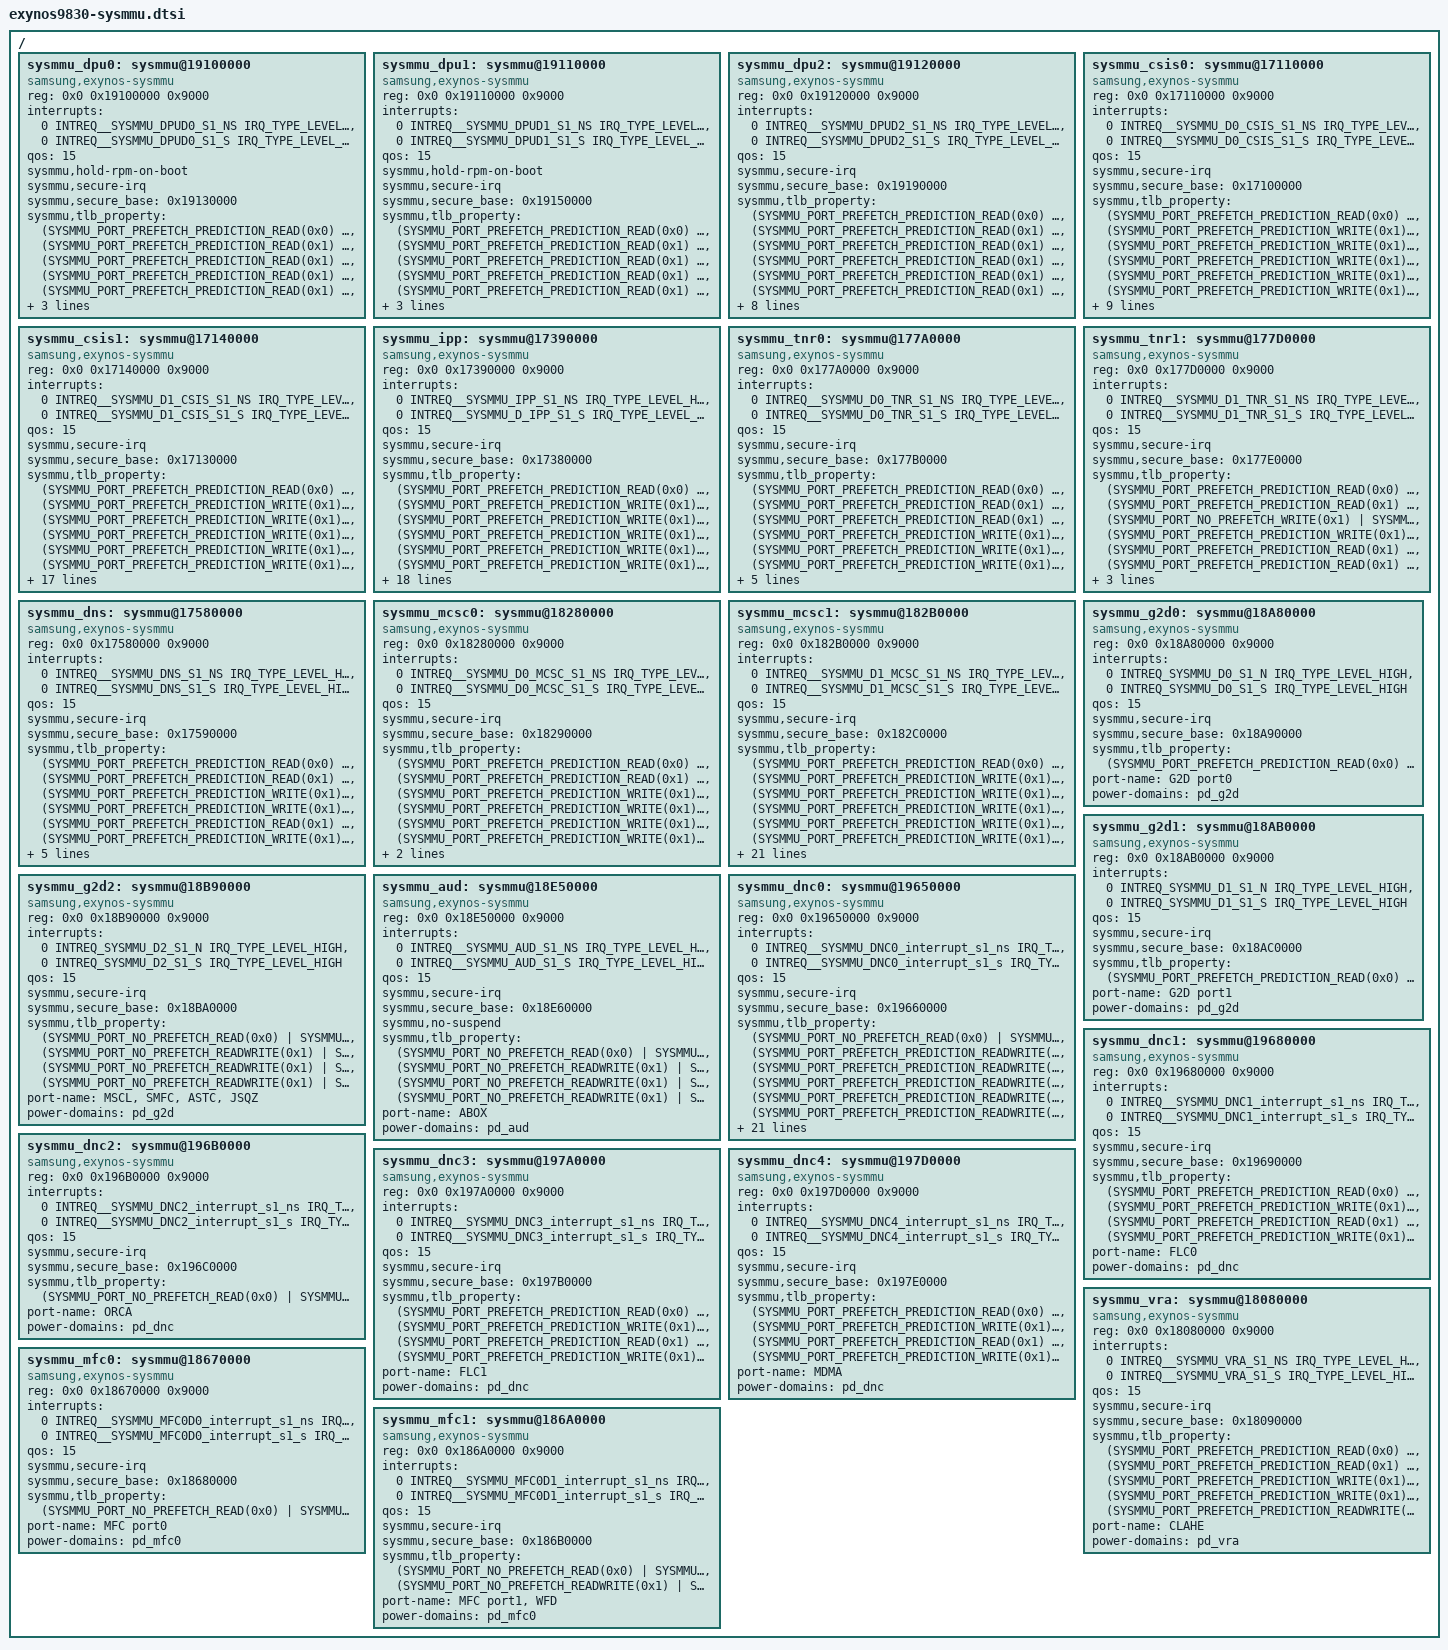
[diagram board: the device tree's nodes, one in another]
/*
 * SAMSUNG EXYNOS9830 SoC device tree source
 *
 * Copyright (c) 2018 Samsung Electronics Co., Ltd.
 *		http://www.samsung.com
 *
 * SAMSUNG EXYNOS9830 SoC device nodes are listed in this file.
 * EXYNOS9830 based board files can include this file and provide
 * values for board specfic bindings.
 *
 * This program is free software; you can redistribute it and/or modify
 * it under the terms of the GNU General Public License version 2 as
 * published by the Free Software Foundation.
 */

#include <dt-bindings/interrupt-controller/arm-gic.h>
#include <dt-bindings/sysmmu/sysmmu.h>

/ {
	sysmmu_dpu0: sysmmu@19100000 {
		compatible = "samsung,exynos-sysmmu";
		reg = <0x0 0x19100000 0x9000>;
		interrupts = <0 INTREQ__SYSMMU_DPUD0_S1_NS IRQ_TYPE_LEVEL_HIGH>,
			     <0 INTREQ__SYSMMU_DPUD0_S1_S IRQ_TYPE_LEVEL_HIGH>;
		qos = <15>;

		sysmmu,hold-rpm-on-boot;
		sysmmu,secure-irq;
		sysmmu,secure_base = <0x19130000>;
		sysmmu,tlb_property =
			<(SYSMMU_PORT_PREFETCH_PREDICTION_READ(0x0) | SYSMMU_BL1)  SYSMMU_NOID>,
			<(SYSMMU_PORT_PREFETCH_PREDICTION_READ(0x1) | SYSMMU_BL1)  SYSMMU_ID_MASK(0x4,  0x1C)>,
			<(SYSMMU_PORT_PREFETCH_PREDICTION_READ(0x1) | SYSMMU_BL32) SYSMMU_ID_MASK(0x10, 0x1C)>,
			<(SYSMMU_PORT_PREFETCH_PREDICTION_READ(0x1) | SYSMMU_BL32) SYSMMU_ID_MASK(0x14, 0x1C)>,
			<(SYSMMU_PORT_PREFETCH_PREDICTION_READ(0x1) | SYSMMU_BL8)  SYSMMU_ID_MASK(0x18, 0x1C)>,
			<(SYSMMU_PORT_PREFETCH_PREDICTION_READ(0x1) | SYSMMU_BL8)  SYSMMU_ID_MASK(0x1C, 0x1C)>;
		port-name = "L0, L5";
		#iommu-cells = <0>;
		power-domains = <&pd_dpu>;
	};

	sysmmu_dpu1: sysmmu@19110000 {
		compatible = "samsung,exynos-sysmmu";
		reg = <0x0 0x19110000 0x9000>;
		interrupts = <0 INTREQ__SYSMMU_DPUD1_S1_NS IRQ_TYPE_LEVEL_HIGH>,
			     <0 INTREQ__SYSMMU_DPUD1_S1_S IRQ_TYPE_LEVEL_HIGH>;
		qos = <15>;

		sysmmu,hold-rpm-on-boot;
		sysmmu,secure-irq;
		sysmmu,secure_base = <0x19150000>;
		sysmmu,tlb_property =
			<(SYSMMU_PORT_PREFETCH_PREDICTION_READ(0x0) | SYSMMU_BL1) SYSMMU_NOID>,
			<(SYSMMU_PORT_PREFETCH_PREDICTION_READ(0x1) | SYSMMU_BL1) SYSMMU_ID_MASK(0x4,  0x1C)>,
			<(SYSMMU_PORT_PREFETCH_PREDICTION_READ(0x1) | SYSMMU_BL1) SYSMMU_ID_MASK(0x10, 0x1C)>,
			<(SYSMMU_PORT_PREFETCH_PREDICTION_READ(0x1) | SYSMMU_BL1) SYSMMU_ID_MASK(0x14, 0x1C)>,
			<(SYSMMU_PORT_PREFETCH_PREDICTION_READ(0x1) | SYSMMU_BL1) SYSMMU_ID_MASK(0x18, 0x1C)>,
			<(SYSMMU_PORT_PREFETCH_PREDICTION_READ(0x1) | SYSMMU_BL1) SYSMMU_ID_MASK(0x1C, 0x1C)>;
		port-name = "L1, L4";
		#iommu-cells = <0>;
		power-domains = <&pd_dpu>;
	};

	sysmmu_dpu2: sysmmu@19120000 {
		compatible = "samsung,exynos-sysmmu";
		reg = <0x0 0x19120000 0x9000>;
		interrupts = <0 INTREQ__SYSMMU_DPUD2_S1_NS IRQ_TYPE_LEVEL_HIGH>,
			     <0 INTREQ__SYSMMU_DPUD2_S1_S IRQ_TYPE_LEVEL_HIGH>;
		qos = <15>;

		sysmmu,secure-irq;
		sysmmu,secure_base = <0x19190000>;
		sysmmu,tlb_property =
			<(SYSMMU_PORT_PREFETCH_PREDICTION_READ(0x0)  | SYSMMU_BL1) SYSMMU_NOID>,
			<(SYSMMU_PORT_PREFETCH_PREDICTION_READ(0x1)  | SYSMMU_BL1) SYSMMU_ID_MASK(0x4,  0x1C)>,
			<(SYSMMU_PORT_PREFETCH_PREDICTION_READ(0x1)  | SYSMMU_BL1) SYSMMU_ID_MASK(0x8,  0x1C)>,
			<(SYSMMU_PORT_PREFETCH_PREDICTION_READ(0x1)  | SYSMMU_BL1) SYSMMU_ID_MASK(0xC,  0x1C)>,
			<(SYSMMU_PORT_PREFETCH_PREDICTION_READ(0x1)  | SYSMMU_BL1) SYSMMU_ID_MASK(0x10, 0x1C)>,
			<(SYSMMU_PORT_PREFETCH_PREDICTION_READ(0x1)  | SYSMMU_BL1) SYSMMU_ID_MASK(0x14, 0x1C)>,
			<(SYSMMU_PORT_PREFETCH_PREDICTION_READ(0x1)  | SYSMMU_BL1) SYSMMU_ID_MASK(0x18, 0x1C)>,
			<(SYSMMU_PORT_PREFETCH_PREDICTION_READ(0x1)  | SYSMMU_BL1) SYSMMU_ID_MASK(0x1C, 0x1C)>,
			<(SYSMMU_PORT_PREFETCH_PREDICTION_WRITE(0x1) | SYSMMU_BL1) SYSMMU_ID_MASK(0x0,  0x18)>,
			<(SYSMMU_PORT_PREFETCH_PREDICTION_WRITE(0x1) | SYSMMU_BL1) SYSMMU_ID_MASK(0x8,  0x18)>,
			<(SYSMMU_PORT_PREFETCH_PREDICTION_WRITE(0x1) | SYSMMU_BL1) SYSMMU_ID_MASK(0x10, 0x18)>,
			<(SYSMMU_PORT_PREFETCH_PREDICTION_WRITE(0x1) | SYSMMU_BL1) SYSMMU_ID_MASK(0x18, 0x18)>;
		port-name = "L2, L3, WB";
		#iommu-cells = <0>;
		power-domains = <&pd_dpu>;
	};

	sysmmu_csis0: sysmmu@17110000 {
		compatible = "samsung,exynos-sysmmu";
		reg = <0x0 0x17110000 0x9000>;
		interrupts = <0 INTREQ__SYSMMU_D0_CSIS_S1_NS IRQ_TYPE_LEVEL_HIGH>,
			     <0 INTREQ__SYSMMU_D0_CSIS_S1_S IRQ_TYPE_LEVEL_HIGH>;
		qos = <15>;

		sysmmu,secure-irq;
		sysmmu,secure_base = <0x17100000>;
		sysmmu,tlb_property =
			<(SYSMMU_PORT_PREFETCH_PREDICTION_READ(0x0)  | SYSMMU_BL1) SYSMMU_NOID>,
			<(SYSMMU_PORT_PREFETCH_PREDICTION_WRITE(0x1) | SYSMMU_BL1) SYSMMU_ID_MASK(0x2,  0x1F)>,
			<(SYSMMU_PORT_PREFETCH_PREDICTION_WRITE(0x1) | SYSMMU_BL1) SYSMMU_ID_MASK(0x4,  0x1F)>,
			<(SYSMMU_PORT_PREFETCH_PREDICTION_WRITE(0x1) | SYSMMU_BL1) SYSMMU_ID_MASK(0x6,  0x1F)>,
			<(SYSMMU_PORT_PREFETCH_PREDICTION_WRITE(0x1) | SYSMMU_BL1) SYSMMU_ID_MASK(0x8,  0x1F)>,
			<(SYSMMU_PORT_PREFETCH_PREDICTION_WRITE(0x1) | SYSMMU_BL1) SYSMMU_ID_MASK(0xA,  0x1F)>,
			<(SYSMMU_PORT_PREFETCH_PREDICTION_WRITE(0x1) | SYSMMU_BL1) SYSMMU_ID_MASK(0xC,  0x1F)>,
			<(SYSMMU_PORT_PREFETCH_PREDICTION_WRITE(0x1) | SYSMMU_BL1) SYSMMU_ID_MASK(0xE,  0x1F)>,
			<(SYSMMU_PORT_PREFETCH_PREDICTION_WRITE(0x1) | SYSMMU_BL1) SYSMMU_ID_MASK(0x1,  0x1F)>,
			<(SYSMMU_PORT_PREFETCH_PREDICTION_WRITE(0x1) | SYSMMU_BL1) SYSMMU_ID_MASK(0x9,  0x1F)>,
			<(SYSMMU_PORT_PREFETCH_PREDICTION_WRITE(0x1) | SYSMMU_BL1) SYSMMU_ID_MASK(0x11, 0x1F)>,
			<(SYSMMU_PORT_PREFETCH_PREDICTION_WRITE(0x1) | SYSMMU_BL1) SYSMMU_ID_MASK(0x19, 0x1F)>,
			<(SYSMMU_PORT_PREFETCH_PREDICTION_WRITE(0x1) | SYSMMU_BL1) SYSMMU_ID_MASK(0x1B, 0x1F)>;
		port-name = "CSIS0";
		#iommu-cells = <0>;
		power-domains = <&pd_csis>;
	};

	sysmmu_csis1: sysmmu@17140000 {
		compatible = "samsung,exynos-sysmmu";
		reg = <0x0 0x17140000 0x9000>;
		interrupts = <0 INTREQ__SYSMMU_D1_CSIS_S1_NS IRQ_TYPE_LEVEL_HIGH>,
			     <0 INTREQ__SYSMMU_D1_CSIS_S1_S IRQ_TYPE_LEVEL_HIGH>;
		qos = <15>;

		sysmmu,secure-irq;
		sysmmu,secure_base = <0x17130000>;
		sysmmu,tlb_property =
			<(SYSMMU_PORT_PREFETCH_PREDICTION_READ(0x0)  | SYSMMU_BL1) SYSMMU_NOID>,
			<(SYSMMU_PORT_PREFETCH_PREDICTION_WRITE(0x1) | SYSMMU_BL1) SYSMMU_ID_MASK(0x4,  0x3F)>,
			<(SYSMMU_PORT_PREFETCH_PREDICTION_WRITE(0x1) | SYSMMU_BL1) SYSMMU_ID_MASK(0x8,  0x3F)>,
			<(SYSMMU_PORT_PREFETCH_PREDICTION_WRITE(0x1) | SYSMMU_BL1) SYSMMU_ID_MASK(0xC,  0x3F)>,
			<(SYSMMU_PORT_PREFETCH_PREDICTION_WRITE(0x1) | SYSMMU_BL1) SYSMMU_ID_MASK(0x10, 0x3F)>,
			<(SYSMMU_PORT_PREFETCH_PREDICTION_WRITE(0x1) | SYSMMU_BL1) SYSMMU_ID_MASK(0x14, 0x3F)>,
			<(SYSMMU_PORT_PREFETCH_PREDICTION_WRITE(0x1) | SYSMMU_BL1) SYSMMU_ID_MASK(0x18, 0x3F)>,
			<(SYSMMU_PORT_PREFETCH_PREDICTION_WRITE(0x1) | SYSMMU_BL1) SYSMMU_ID_MASK(0x1C, 0x3F)>,
			<(SYSMMU_PORT_PREFETCH_PREDICTION_WRITE(0x1) | SYSMMU_BL1) SYSMMU_ID_MASK(0x1,  0x3F)>,
			<(SYSMMU_PORT_PREFETCH_PREDICTION_WRITE(0x1) | SYSMMU_BL1) SYSMMU_ID_MASK(0x11, 0x3F)>,
			<(SYSMMU_PORT_PREFETCH_PREDICTION_WRITE(0x1) | SYSMMU_BL1) SYSMMU_ID_MASK(0x21, 0x3F)>,
			<(SYSMMU_PORT_PREFETCH_PREDICTION_WRITE(0x1) | SYSMMU_BL1) SYSMMU_ID_MASK(0x31, 0x3F)>,
			<(SYSMMU_PORT_PREFETCH_PREDICTION_WRITE(0x1) | SYSMMU_BL1) SYSMMU_ID_MASK(0x35, 0x3F)>,
			<(SYSMMU_PORT_PREFETCH_PREDICTION_WRITE(0x1) | SYSMMU_BL1) SYSMMU_ID_MASK(0xA,  0x3F)>,
			<(SYSMMU_PORT_PREFETCH_PREDICTION_WRITE(0x1) | SYSMMU_BL1) SYSMMU_ID_MASK(0x1A, 0x3F)>,
			<(SYSMMU_PORT_PREFETCH_PREDICTION_READ(0x1)  | SYSMMU_BL1) SYSMMU_ID_MASK(0x2,  0x3F)>,
			<(SYSMMU_PORT_PREFETCH_PREDICTION_READ(0x1)  | SYSMMU_BL1) SYSMMU_ID_MASK(0x6,  0x3F)>,
			<(SYSMMU_PORT_PREFETCH_PREDICTION_READ(0x1)  | SYSMMU_BL1) SYSMMU_ID_MASK(0xA,  0x3F)>,
			<(SYSMMU_PORT_PREFETCH_PREDICTION_READ(0x1)  | SYSMMU_BL1) SYSMMU_ID_MASK(0x12, 0x3F)>,
			<(SYSMMU_PORT_PREFETCH_PREDICTION_READ(0x1)  | SYSMMU_BL1) SYSMMU_ID_MASK(0x16, 0x3F)>,
			<(SYSMMU_PORT_PREFETCH_PREDICTION_READ(0x1)  | SYSMMU_BL1) SYSMMU_ID_MASK(0x1A, 0x3F)>;
		port-name = "CSIS1";
		#iommu-cells = <0>;
		power-domains = <&pd_csis>;
	};

	sysmmu_ipp: sysmmu@17390000 {
		compatible = "samsung,exynos-sysmmu";
		reg = <0x0 0x17390000 0x9000>;
		interrupts = <0 INTREQ__SYSMMU_IPP_S1_NS IRQ_TYPE_LEVEL_HIGH>,
			     <0 INTREQ__SYSMMU_D_IPP_S1_S IRQ_TYPE_LEVEL_HIGH>;
		qos = <15>;

		sysmmu,secure-irq;
		sysmmu,secure_base = <0x17380000>;
		sysmmu,tlb_property =
			<(SYSMMU_PORT_PREFETCH_PREDICTION_READ(0x0)  | SYSMMU_BL1) SYSMMU_NOID>,
			<(SYSMMU_PORT_PREFETCH_PREDICTION_WRITE(0x1) | SYSMMU_BL1) SYSMMU_ID_MASK(0x40, 0xFF)>,
			<(SYSMMU_PORT_PREFETCH_PREDICTION_WRITE(0x1) | SYSMMU_BL1) SYSMMU_ID_MASK(0x1,  0xFF)>,
			<(SYSMMU_PORT_PREFETCH_PREDICTION_WRITE(0x1) | SYSMMU_BL1) SYSMMU_ID_MASK(0x41, 0xFF)>,
			<(SYSMMU_PORT_PREFETCH_PREDICTION_WRITE(0x1) | SYSMMU_BL1) SYSMMU_ID_MASK(0x2,  0xFF)>,
			<(SYSMMU_PORT_PREFETCH_PREDICTION_WRITE(0x1) | SYSMMU_BL1) SYSMMU_ID_MASK(0x42, 0xFF)>,
			<(SYSMMU_PORT_PREFETCH_PREDICTION_WRITE(0x1) | SYSMMU_BL1) SYSMMU_ID_MASK(0x82, 0xFF)>,
			<(SYSMMU_PORT_PREFETCH_PREDICTION_WRITE(0x1) | SYSMMU_BL1) SYSMMU_ID_MASK(0x3,  0xFF)>,
			<(SYSMMU_PORT_PREFETCH_PREDICTION_WRITE(0x1) | SYSMMU_BL1) SYSMMU_ID_MASK(0x43, 0xFF)>,
			<(SYSMMU_PORT_PREFETCH_PREDICTION_WRITE(0x1) | SYSMMU_BL1) SYSMMU_ID_MASK(0x83, 0xFF)>,
			<(SYSMMU_PORT_PREFETCH_PREDICTION_WRITE(0x1) | SYSMMU_BL1) SYSMMU_ID_MASK(0x4,  0xFF)>,
			<(SYSMMU_PORT_PREFETCH_PREDICTION_WRITE(0x1) | SYSMMU_BL1) SYSMMU_ID_MASK(0x14, 0xFF)>,
			<(SYSMMU_PORT_PREFETCH_PREDICTION_WRITE(0x1) | SYSMMU_BL1) SYSMMU_ID_MASK(0x24, 0xFF)>,
			<(SYSMMU_PORT_PREFETCH_PREDICTION_WRITE(0x1) | SYSMMU_BL1) SYSMMU_ID_MASK(0x44, 0xFF)>,
			<(SYSMMU_PORT_PREFETCH_PREDICTION_WRITE(0x1) | SYSMMU_BL1) SYSMMU_ID_MASK(0x54, 0xFF)>,
			<(SYSMMU_PORT_PREFETCH_PREDICTION_WRITE(0x1) | SYSMMU_BL1) SYSMMU_ID_MASK(0x64, 0xFF)>,
			<(SYSMMU_PORT_PREFETCH_PREDICTION_WRITE(0x1) | SYSMMU_BL1) SYSMMU_ID_MASK(0x84, 0xFF)>,
			<(SYSMMU_PORT_PREFETCH_PREDICTION_WRITE(0x1) | SYSMMU_BL1) SYSMMU_ID_MASK(0x94, 0xFF)>,
			<(SYSMMU_PORT_PREFETCH_PREDICTION_WRITE(0x1) | SYSMMU_BL1) SYSMMU_ID_MASK(0xA4, 0xFF)>,
			<(SYSMMU_PORT_PREFETCH_PREDICTION_WRITE(0x1) | SYSMMU_BL1) SYSMMU_ID_MASK(0x5,  0xFF)>,
			<(SYSMMU_PORT_PREFETCH_PREDICTION_WRITE(0x1) | SYSMMU_BL1) SYSMMU_ID_MASK(0x46, 0xFF)>,
			<(SYSMMU_PORT_PREFETCH_PREDICTION_WRITE(0x1) | SYSMMU_BL1) SYSMMU_ID_MASK(0x87, 0xFF)>;
		port-name = "SIPU_IPP";
		#iommu-cells = <0>;
		power-domains = <&pd_ipp>;
	};

	sysmmu_tnr0: sysmmu@177A0000 {
		compatible = "samsung,exynos-sysmmu";
		reg = <0x0 0x177A0000 0x9000>;
		interrupts = <0 INTREQ__SYSMMU_D0_TNR_S1_NS IRQ_TYPE_LEVEL_HIGH>,
			     <0 INTREQ__SYSMMU_D0_TNR_S1_S IRQ_TYPE_LEVEL_HIGH>;
		qos = <15>;

		sysmmu,secure-irq;
		sysmmu,secure_base = <0x177B0000>;
		sysmmu,tlb_property =
			<(SYSMMU_PORT_PREFETCH_PREDICTION_READ(0x0)  | SYSMMU_BL32) SYSMMU_NOID>,
			<(SYSMMU_PORT_PREFETCH_PREDICTION_READ(0x1)  | SYSMMU_BL16) SYSMMU_ID_MASK(0x43, 0x7F)>,
			<(SYSMMU_PORT_PREFETCH_PREDICTION_READ(0x1)  | SYSMMU_BL2)  SYSMMU_ID_MASK(0x7,  0x7F)>,
			<(SYSMMU_PORT_PREFETCH_PREDICTION_WRITE(0x1) | SYSMMU_BL1)  SYSMMU_ID_MASK(0x3,  0x7F)>,
			<(SYSMMU_PORT_PREFETCH_PREDICTION_WRITE(0x1) | SYSMMU_BL1)  SYSMMU_ID_MASK(0x7,  0x7F)>,
			<(SYSMMU_PORT_PREFETCH_PREDICTION_WRITE(0x1) | SYSMMU_BL1)  SYSMMU_ID_MASK(0xB,  0x7F)>,
			<(SYSMMU_PORT_PREFETCH_PREDICTION_READ(0x1)  | SYSMMU_BL1)  SYSMMU_ID_MASK(0x0,  0x7F)>,
			<(SYSMMU_PORT_PREFETCH_PREDICTION_WRITE(0x1) | SYSMMU_BL1)  SYSMMU_ID_MASK(0x0,  0x7F)>,
			<(SYSMMU_PORT_PREFETCH_PREDICTION_READ(0x1)  | SYSMMU_BL1)  SYSMMU_ID_MASK(0x1,  0x7F)>;
		port-name = "TNR0";
		#iommu-cells = <0>;
		power-domains = <&pd_tnr>;
	};

	sysmmu_tnr1: sysmmu@177D0000 {
		compatible = "samsung,exynos-sysmmu";
		reg = <0x0 0x177D0000 0x9000>;
		interrupts = <0 INTREQ__SYSMMU_D1_TNR_S1_NS IRQ_TYPE_LEVEL_HIGH>,
			     <0 INTREQ__SYSMMU_D1_TNR_S1_S IRQ_TYPE_LEVEL_HIGH>;
		qos = <15>;

		sysmmu,secure-irq;
		sysmmu,secure_base = <0x177E0000>;
		sysmmu,tlb_property =
			<(SYSMMU_PORT_PREFETCH_PREDICTION_READ(0x0)  | SYSMMU_BL16) SYSMMU_NOID>,
			<(SYSMMU_PORT_PREFETCH_PREDICTION_READ(0x1)  | SYSMMU_BL4)  SYSMMU_ID_MASK(0x1, 0x7)>,
			<(SYSMMU_PORT_NO_PREFETCH_WRITE(0x1)         | SYSMMU_BL4)  SYSMMU_ID_MASK(0x1, 0x7)>,
			<(SYSMMU_PORT_PREFETCH_PREDICTION_WRITE(0x1) | SYSMMU_BL1)  SYSMMU_ID_MASK(0x2, 0x7)>,
			<(SYSMMU_PORT_PREFETCH_PREDICTION_READ(0x1)  | SYSMMU_BL1)  SYSMMU_ID_MASK(0x0, 0x7)>,
			<(SYSMMU_PORT_PREFETCH_PREDICTION_READ(0x1)  | SYSMMU_BL1)  SYSMMU_ID_MASK(0x4, 0x7)>,
			<(SYSMMU_PORT_PREFETCH_PREDICTION_WRITE(0x1) | SYSMMU_BL1)  SYSMMU_ID_MASK(0x0, 0x7)>;
		port-name = "TNR1";
		#iommu-cells = <0>;
		power-domains = <&pd_tnr>;
	};

	sysmmu_dns: sysmmu@17580000 {
		compatible = "samsung,exynos-sysmmu";
		reg = <0x0 0x17580000 0x9000>;
		interrupts = <0 INTREQ__SYSMMU_DNS_S1_NS IRQ_TYPE_LEVEL_HIGH>,
			     <0 INTREQ__SYSMMU_DNS_S1_S IRQ_TYPE_LEVEL_HIGH>;
		qos = <15>;

		sysmmu,secure-irq;
		sysmmu,secure_base = <0x17590000>;
		sysmmu,tlb_property =
			<(SYSMMU_PORT_PREFETCH_PREDICTION_READ(0x0)  | SYSMMU_BL1) SYSMMU_NOID>,
			<(SYSMMU_PORT_PREFETCH_PREDICTION_READ(0x1)  | SYSMMU_BL1) SYSMMU_ID_MASK(0x4, 0x3F)>,
			<(SYSMMU_PORT_PREFETCH_PREDICTION_WRITE(0x1) | SYSMMU_BL1) SYSMMU_ID_MASK(0x0, 0x3F)>,
			<(SYSMMU_PORT_PREFETCH_PREDICTION_WRITE(0x1) | SYSMMU_BL1) SYSMMU_ID_MASK(0x8, 0x3F)>,
			<(SYSMMU_PORT_PREFETCH_PREDICTION_READ(0x1)  | SYSMMU_BL1) SYSMMU_ID_MASK(0x1, 0x3F)>,
			<(SYSMMU_PORT_PREFETCH_PREDICTION_WRITE(0x1) | SYSMMU_BL1) SYSMMU_ID_MASK(0x1, 0x3F)>,
			<(SYSMMU_PORT_PREFETCH_PREDICTION_READ(0x1)  | SYSMMU_BL1) SYSMMU_ID_MASK(0x2, 0x3F)>,
			<(SYSMMU_PORT_PREFETCH_PREDICTION_WRITE(0x1) | SYSMMU_BL1) SYSMMU_ID_MASK(0x2, 0x3F)>,
			<(SYSMMU_PORT_PREFETCH_PREDICTION_READ(0x1)  | SYSMMU_BL1) SYSMMU_ID_MASK(0x3, 0x3F)>;
		port-name = "DNS";
		#iommu-cells = <0>;
		power-domains = <&pd_dns>;
	};

	sysmmu_mcsc0: sysmmu@18280000 {
		compatible = "samsung,exynos-sysmmu";
		reg = <0x0 0x18280000 0x9000>;
		interrupts = <0 INTREQ__SYSMMU_D0_MCSC_S1_NS IRQ_TYPE_LEVEL_HIGH>,
			     <0 INTREQ__SYSMMU_D0_MCSC_S1_S IRQ_TYPE_LEVEL_HIGH>;
		qos = <15>;

		sysmmu,secure-irq;
		sysmmu,secure_base = <0x18290000>;
		sysmmu,tlb_property =
			<(SYSMMU_PORT_PREFETCH_PREDICTION_READ(0x0)  | SYSMMU_BL32) SYSMMU_NOID>,
			<(SYSMMU_PORT_PREFETCH_PREDICTION_READ(0x1)  | SYSMMU_BL32) SYSMMU_ID_MASK(0x4, 0x7)>,
			<(SYSMMU_PORT_PREFETCH_PREDICTION_WRITE(0x1) | SYSMMU_BL16) SYSMMU_ID_MASK(0x0, 0x7)>,
			<(SYSMMU_PORT_PREFETCH_PREDICTION_WRITE(0x1) | SYSMMU_BL16) SYSMMU_ID_MASK(0x2, 0x7)>,
			<(SYSMMU_PORT_PREFETCH_PREDICTION_WRITE(0x1) | SYSMMU_BL1)  SYSMMU_ID_MASK(0x1, 0x7)>,
			<(SYSMMU_PORT_PREFETCH_PREDICTION_WRITE(0x1) | SYSMMU_BL1)  SYSMMU_ID_MASK(0x3, 0x7)>;
		port-name = "GDC0";
		#iommu-cells = <0>;
		power-domains = <&pd_mcsc>;
	};

	sysmmu_mcsc1: sysmmu@182B0000 {
		compatible = "samsung,exynos-sysmmu";
		reg = <0x0 0x182B0000 0x9000>;
		interrupts = <0 INTREQ__SYSMMU_D1_MCSC_S1_NS IRQ_TYPE_LEVEL_HIGH>,
			     <0 INTREQ__SYSMMU_D1_MCSC_S1_S IRQ_TYPE_LEVEL_HIGH>;
		qos = <15>;

		sysmmu,secure-irq;
		sysmmu,secure_base = <0x182C0000>;
		sysmmu,tlb_property =
			<(SYSMMU_PORT_PREFETCH_PREDICTION_READ(0x0)  | SYSMMU_BL1) SYSMMU_NOID>,
			<(SYSMMU_PORT_PREFETCH_PREDICTION_WRITE(0x1) | SYSMMU_BL1) SYSMMU_ID_MASK(0x1,  0x3F)>,
			<(SYSMMU_PORT_PREFETCH_PREDICTION_WRITE(0x1) | SYSMMU_BL1) SYSMMU_ID_MASK(0x2,  0x3F)>,
			<(SYSMMU_PORT_PREFETCH_PREDICTION_WRITE(0x1) | SYSMMU_BL1) SYSMMU_ID_MASK(0x3,  0x3F)>,
			<(SYSMMU_PORT_PREFETCH_PREDICTION_WRITE(0x1) | SYSMMU_BL1) SYSMMU_ID_MASK(0x4,  0x3F)>,
			<(SYSMMU_PORT_PREFETCH_PREDICTION_WRITE(0x1) | SYSMMU_BL1) SYSMMU_ID_MASK(0x7,  0x3F)>,
			<(SYSMMU_PORT_PREFETCH_PREDICTION_WRITE(0x1) | SYSMMU_BL1) SYSMMU_ID_MASK(0x8,  0x3F)>,
			<(SYSMMU_PORT_PREFETCH_PREDICTION_WRITE(0x1) | SYSMMU_BL1) SYSMMU_ID_MASK(0x9,  0x3F)>,
			<(SYSMMU_PORT_PREFETCH_PREDICTION_WRITE(0x1) | SYSMMU_BL1) SYSMMU_ID_MASK(0xA,  0x3F)>,
			<(SYSMMU_PORT_PREFETCH_PREDICTION_WRITE(0x1) | SYSMMU_BL1) SYSMMU_ID_MASK(0xB,  0x3F)>,
			<(SYSMMU_PORT_PREFETCH_PREDICTION_WRITE(0x1) | SYSMMU_BL1) SYSMMU_ID_MASK(0xE,  0x3F)>,
			<(SYSMMU_PORT_PREFETCH_PREDICTION_WRITE(0x1) | SYSMMU_BL1) SYSMMU_ID_MASK(0xF,  0x3F)>,
			<(SYSMMU_PORT_PREFETCH_PREDICTION_WRITE(0x1) | SYSMMU_BL1) SYSMMU_ID_MASK(0x10, 0x3F)>,
			<(SYSMMU_PORT_PREFETCH_PREDICTION_WRITE(0x1) | SYSMMU_BL1) SYSMMU_ID_MASK(0x11, 0x3F)>,
			<(SYSMMU_PORT_PREFETCH_PREDICTION_WRITE(0x1) | SYSMMU_BL1) SYSMMU_ID_MASK(0x12, 0x3F)>,
			<(SYSMMU_PORT_PREFETCH_PREDICTION_WRITE(0x1) | SYSMMU_BL1) SYSMMU_ID_MASK(0x15, 0x3F)>,
			<(SYSMMU_PORT_PREFETCH_PREDICTION_WRITE(0x1) | SYSMMU_BL1) SYSMMU_ID_MASK(0x16, 0x3F)>,
			<(SYSMMU_PORT_PREFETCH_PREDICTION_WRITE(0x1) | SYSMMU_BL1) SYSMMU_ID_MASK(0x17, 0x3F)>,
			<(SYSMMU_PORT_PREFETCH_PREDICTION_WRITE(0x1) | SYSMMU_BL1) SYSMMU_ID_MASK(0x18, 0x3F)>,
			<(SYSMMU_PORT_PREFETCH_PREDICTION_WRITE(0x1) | SYSMMU_BL1) SYSMMU_ID_MASK(0x19, 0x3F)>,
			<(SYSMMU_PORT_PREFETCH_PREDICTION_WRITE(0x1) | SYSMMU_BL1) SYSMMU_ID_MASK(0x1C, 0x3F)>,
			<(SYSMMU_PORT_PREFETCH_PREDICTION_WRITE(0x1) | SYSMMU_BL1) SYSMMU_ID_MASK(0x1D, 0x3F)>,
			<(SYSMMU_PORT_PREFETCH_PREDICTION_WRITE(0x1) | SYSMMU_BL1) SYSMMU_ID_MASK(0x1E, 0x3F)>,
			<(SYSMMU_PORT_PREFETCH_PREDICTION_WRITE(0x1) | SYSMMU_BL1) SYSMMU_ID_MASK(0x1F, 0x3F)>,
			<(SYSMMU_PORT_PREFETCH_PREDICTION_WRITE(0x1) | SYSMMU_BL1) SYSMMU_ID_MASK(0x20, 0x3F)>;
		port-name = "MCSC";
		#iommu-cells = <0>;
		power-domains = <&pd_mcsc>;
	};

	sysmmu_g2d0: sysmmu@18A80000 {
		compatible = "samsung,exynos-sysmmu";
		reg = <0x0 0x18A80000 0x9000>;
		interrupts = <0 INTREQ_SYSMMU_D0_S1_N IRQ_TYPE_LEVEL_HIGH>,
			     <0 INTREQ_SYSMMU_D0_S1_S IRQ_TYPE_LEVEL_HIGH>;
		qos = <15>;

		sysmmu,secure-irq;
		sysmmu,secure_base = <0x18A90000>;
		sysmmu,tlb_property =
			<(SYSMMU_PORT_PREFETCH_PREDICTION_READ(0x0) | SYSMMU_BL32) SYSMMU_NOID>;
		port-name = "G2D port0";
		#iommu-cells = <0>;
		power-domains = <&pd_g2d>;
	};

	sysmmu_g2d1: sysmmu@18AB0000 {
		compatible = "samsung,exynos-sysmmu";
		reg = <0x0 0x18AB0000 0x9000>;
		interrupts = <0 INTREQ_SYSMMU_D1_S1_N IRQ_TYPE_LEVEL_HIGH>,
			     <0 INTREQ_SYSMMU_D1_S1_S IRQ_TYPE_LEVEL_HIGH>;
		qos = <15>;

		sysmmu,secure-irq;
		sysmmu,secure_base = <0x18AC0000>;
		sysmmu,tlb_property =
			<(SYSMMU_PORT_PREFETCH_PREDICTION_READ(0x0) | SYSMMU_BL32) SYSMMU_NOID>;
		port-name = "G2D port1";
		#iommu-cells = <0>;
		power-domains = <&pd_g2d>;
	};

	sysmmu_g2d2: sysmmu@18B90000 {
		compatible = "samsung,exynos-sysmmu";
		reg = <0x0 0x18B90000 0x9000>;
		interrupts = <0 INTREQ_SYSMMU_D2_S1_N IRQ_TYPE_LEVEL_HIGH>,
			     <0 INTREQ_SYSMMU_D2_S1_S IRQ_TYPE_LEVEL_HIGH>;
		qos = <15>;

		sysmmu,secure-irq;
		sysmmu,secure_base = <0x18BA0000>;
		sysmmu,tlb_property =
			<(SYSMMU_PORT_NO_PREFETCH_READ(0x0)      | SYSMMU_BL32) SYSMMU_NOID>,
			<(SYSMMU_PORT_NO_PREFETCH_READWRITE(0x1) | SYSMMU_BL8) SYSMMU_ID_MASK(0x0, 0x3)>,
			<(SYSMMU_PORT_NO_PREFETCH_READWRITE(0x1) | SYSMMU_BL1) SYSMMU_ID_MASK(0x2, 0x3)>,
			<(SYSMMU_PORT_NO_PREFETCH_READWRITE(0x1) | SYSMMU_BL1) SYSMMU_ID_MASK(0x3, 0x3)>;
		port-name = "MSCL, SMFC, ASTC, JSQZ";
		#iommu-cells = <0>;
		power-domains = <&pd_g2d>;
	};

	sysmmu_aud: sysmmu@18E50000 {
		compatible = "samsung,exynos-sysmmu";
		reg = <0x0 0x18E50000 0x9000>;
		interrupts = <0 INTREQ__SYSMMU_AUD_S1_NS IRQ_TYPE_LEVEL_HIGH>,
			     <0 INTREQ__SYSMMU_AUD_S1_S IRQ_TYPE_LEVEL_HIGH>;
		qos = <15>;

		sysmmu,secure-irq;
		sysmmu,secure_base = <0x18E60000>;
		sysmmu,no-suspend;
		sysmmu,tlb_property =
			<(SYSMMU_PORT_NO_PREFETCH_READ(0x0)      | SYSMMU_BL1) SYSMMU_NOID>,
			<(SYSMMU_PORT_NO_PREFETCH_READWRITE(0x1) | SYSMMU_BL1) SYSMMU_ID_MASK(0x2, 0x3)>,
			<(SYSMMU_PORT_NO_PREFETCH_READWRITE(0x1) | SYSMMU_BL1) SYSMMU_ID_MASK(0x6, 0xF)>,
			<(SYSMMU_PORT_NO_PREFETCH_READWRITE(0x1) | SYSMMU_BL1) SYSMMU_ID_MASK(0x0, 0xF)>;
		port-name = "ABOX";
		#iommu-cells = <0>;
		power-domains = <&pd_aud>;
	};

	sysmmu_dnc0: sysmmu@19650000 {
		compatible = "samsung,exynos-sysmmu";
		reg = <0x0 0x19650000 0x9000>;
		interrupts = <0 INTREQ__SYSMMU_DNC0_interrupt_s1_ns IRQ_TYPE_LEVEL_HIGH>,
			     <0 INTREQ__SYSMMU_DNC0_interrupt_s1_s IRQ_TYPE_LEVEL_HIGH>;
		qos = <15>;

		sysmmu,secure-irq;
		sysmmu,secure_base = <0x19660000>;
		sysmmu,tlb_property =
			<(SYSMMU_PORT_NO_PREFETCH_READ(0x0)              | SYSMMU_BL8) SYSMMU_NOID>,
			<(SYSMMU_PORT_PREFETCH_PREDICTION_READWRITE(0x1) | SYSMMU_BL16) SYSMMU_ID_MASK(0x0,  0x201F)>,
			<(SYSMMU_PORT_PREFETCH_PREDICTION_READWRITE(0x1) | SYSMMU_BL16) SYSMMU_ID_MASK(0x1,  0x201F)>,
			<(SYSMMU_PORT_PREFETCH_PREDICTION_READWRITE(0x1) | SYSMMU_BL16) SYSMMU_ID_MASK(0x2,  0x201F)>,
			<(SYSMMU_PORT_PREFETCH_PREDICTION_READWRITE(0x1) | SYSMMU_BL16) SYSMMU_ID_MASK(0x3,  0x201F)>,
			<(SYSMMU_PORT_PREFETCH_PREDICTION_READWRITE(0x1) | SYSMMU_BL16) SYSMMU_ID_MASK(0x4,  0x201F)>,
			<(SYSMMU_PORT_PREFETCH_PREDICTION_READWRITE(0x1) | SYSMMU_BL16) SYSMMU_ID_MASK(0x5,  0x201F)>,
			<(SYSMMU_PORT_PREFETCH_PREDICTION_READWRITE(0x1) | SYSMMU_BL16) SYSMMU_ID_MASK(0x6,  0x201F)>,
			<(SYSMMU_PORT_PREFETCH_PREDICTION_READWRITE(0x1) | SYSMMU_BL16) SYSMMU_ID_MASK(0x7,  0x201F)>,
			<(SYSMMU_PORT_PREFETCH_PREDICTION_READWRITE(0x1) | SYSMMU_BL16) SYSMMU_ID_MASK(0x8,  0x201F)>,
			<(SYSMMU_PORT_PREFETCH_PREDICTION_READWRITE(0x1) | SYSMMU_BL16) SYSMMU_ID_MASK(0x9,  0x201F)>,
			<(SYSMMU_PORT_PREFETCH_PREDICTION_READWRITE(0x1) | SYSMMU_BL16) SYSMMU_ID_MASK(0xA,  0x201F)>,
			<(SYSMMU_PORT_PREFETCH_PREDICTION_READWRITE(0x1) | SYSMMU_BL16) SYSMMU_ID_MASK(0xB,  0x201F)>,
			<(SYSMMU_PORT_PREFETCH_PREDICTION_READWRITE(0x1) | SYSMMU_BL16) SYSMMU_ID_MASK(0xC,  0x201F)>,
			<(SYSMMU_PORT_PREFETCH_PREDICTION_READWRITE(0x1) | SYSMMU_BL16) SYSMMU_ID_MASK(0xD,  0x201F)>,
			<(SYSMMU_PORT_PREFETCH_PREDICTION_READWRITE(0x1) | SYSMMU_BL16) SYSMMU_ID_MASK(0xE,  0x201F)>,
			<(SYSMMU_PORT_PREFETCH_PREDICTION_READWRITE(0x1) | SYSMMU_BL16) SYSMMU_ID_MASK(0xF,  0x201F)>,
			<(SYSMMU_PORT_PREFETCH_PREDICTION_READWRITE(0x1) | SYSMMU_BL16) SYSMMU_ID_MASK(0x10, 0x201F)>,
			<(SYSMMU_PORT_PREFETCH_PREDICTION_READWRITE(0x1) | SYSMMU_BL16) SYSMMU_ID_MASK(0x11, 0x201F)>,
			<(SYSMMU_PORT_PREFETCH_PREDICTION_READWRITE(0x1) | SYSMMU_BL16) SYSMMU_ID_MASK(0x12, 0x201F)>,
			<(SYSMMU_PORT_PREFETCH_PREDICTION_READWRITE(0x1) | SYSMMU_BL16) SYSMMU_ID_MASK(0x13, 0x201F)>,
			<(SYSMMU_PORT_PREFETCH_PREDICTION_READWRITE(0x1) | SYSMMU_BL16) SYSMMU_ID_MASK(0x14, 0x201F)>,
			<(SYSMMU_PORT_PREFETCH_PREDICTION_READWRITE(0x1) | SYSMMU_BL16) SYSMMU_ID_MASK(0x15, 0x201F)>,
			<(SYSMMU_PORT_PREFETCH_PREDICTION_READWRITE(0x1) | SYSMMU_BL16) SYSMMU_ID_MASK(0x16, 0x201F)>,
			<(SYSMMU_PORT_PREFETCH_PREDICTION_READWRITE(0x1) | SYSMMU_BL16) SYSMMU_ID_MASK(0x17, 0x201F)>;
		port-name = "SDMA";
		#iommu-cells = <0>;
		power-domains = <&pd_dnc>;
	};

	sysmmu_dnc1: sysmmu@19680000 {
		compatible = "samsung,exynos-sysmmu";
		reg = <0x0 0x19680000 0x9000>;
		interrupts = <0 INTREQ__SYSMMU_DNC1_interrupt_s1_ns IRQ_TYPE_LEVEL_HIGH>,
			     <0 INTREQ__SYSMMU_DNC1_interrupt_s1_s IRQ_TYPE_LEVEL_HIGH>;
		qos = <15>;

		sysmmu,secure-irq;
		sysmmu,secure_base = <0x19690000>;
		sysmmu,tlb_property =
			<(SYSMMU_PORT_PREFETCH_PREDICTION_READ(0x0)  | SYSMMU_BL16) SYSMMU_NOID>,
			<(SYSMMU_PORT_PREFETCH_PREDICTION_WRITE(0x1) | SYSMMU_BL16) SYSMMU_ID_MASK(0x0,  0x80)>,
			<(SYSMMU_PORT_PREFETCH_PREDICTION_READ(0x1)  | SYSMMU_BL16) SYSMMU_ID_MASK(0x80, 0x80)>,
			<(SYSMMU_PORT_PREFETCH_PREDICTION_WRITE(0x1) | SYSMMU_BL16) SYSMMU_ID_MASK(0x80, 0x80)>;
		port-name = "FLC0";
		#iommu-cells = <0>;
		power-domains = <&pd_dnc>;
	};

	sysmmu_dnc2: sysmmu@196B0000 {
		compatible = "samsung,exynos-sysmmu";
		reg = <0x0 0x196B0000 0x9000>;
		interrupts = <0 INTREQ__SYSMMU_DNC2_interrupt_s1_ns IRQ_TYPE_LEVEL_HIGH>,
			     <0 INTREQ__SYSMMU_DNC2_interrupt_s1_s IRQ_TYPE_LEVEL_HIGH>;
		qos = <15>;

		sysmmu,secure-irq;
		sysmmu,secure_base = <0x196C0000>;
		sysmmu,tlb_property =
			<(SYSMMU_PORT_NO_PREFETCH_READ(0x0) | SYSMMU_BL1) SYSMMU_NOID>;
		port-name = "ORCA";
		#iommu-cells = <0>;
		power-domains = <&pd_dnc>;
	};

	sysmmu_dnc3: sysmmu@197A0000 {
		compatible = "samsung,exynos-sysmmu";
		reg = <0x0 0x197A0000 0x9000>;
		interrupts = <0 INTREQ__SYSMMU_DNC3_interrupt_s1_ns IRQ_TYPE_LEVEL_HIGH>,
			     <0 INTREQ__SYSMMU_DNC3_interrupt_s1_s IRQ_TYPE_LEVEL_HIGH>;
		qos = <15>;

		sysmmu,secure-irq;
		sysmmu,secure_base = <0x197B0000>;
		sysmmu,tlb_property =
			<(SYSMMU_PORT_PREFETCH_PREDICTION_READ(0x0)  | SYSMMU_BL16) SYSMMU_NOID>,
			<(SYSMMU_PORT_PREFETCH_PREDICTION_WRITE(0x1) | SYSMMU_BL16) SYSMMU_ID_MASK(0x0,  0x80)>,
			<(SYSMMU_PORT_PREFETCH_PREDICTION_READ(0x1)  | SYSMMU_BL16) SYSMMU_ID_MASK(0x80, 0x80)>,
			<(SYSMMU_PORT_PREFETCH_PREDICTION_WRITE(0x1) | SYSMMU_BL16) SYSMMU_ID_MASK(0x80, 0x80)>;
		port-name = "FLC1";
		#iommu-cells = <0>;
		power-domains = <&pd_dnc>;
	};

	sysmmu_dnc4: sysmmu@197D0000 {
		compatible = "samsung,exynos-sysmmu";
		reg = <0x0 0x197D0000 0x9000>;
		interrupts = <0 INTREQ__SYSMMU_DNC4_interrupt_s1_ns IRQ_TYPE_LEVEL_HIGH>,
			     <0 INTREQ__SYSMMU_DNC4_interrupt_s1_s IRQ_TYPE_LEVEL_HIGH>;
		qos = <15>;

		sysmmu,secure-irq;
		sysmmu,secure_base = <0x197E0000>;
		sysmmu,tlb_property =
			<(SYSMMU_PORT_PREFETCH_PREDICTION_READ(0x0)  | SYSMMU_BL16) SYSMMU_NOID>,
			<(SYSMMU_PORT_PREFETCH_PREDICTION_WRITE(0x1) | SYSMMU_BL16) SYSMMU_ID_MASK(0x1, 0x3)>,
			<(SYSMMU_PORT_PREFETCH_PREDICTION_READ(0x1)  | SYSMMU_BL16) SYSMMU_ID_MASK(0x2, 0x3)>,
			<(SYSMMU_PORT_PREFETCH_PREDICTION_WRITE(0x1) | SYSMMU_BL16) SYSMMU_ID_MASK(0x3, 0x3)>;
		port-name = "MDMA";
		#iommu-cells = <0>;
		power-domains = <&pd_dnc>;
	};

	sysmmu_vra: sysmmu@18080000 {
		compatible = "samsung,exynos-sysmmu";
		reg = <0x0 0x18080000 0x9000>;
		interrupts = <0 INTREQ__SYSMMU_VRA_S1_NS IRQ_TYPE_LEVEL_HIGH>,
			     <0 INTREQ__SYSMMU_VRA_S1_S IRQ_TYPE_LEVEL_HIGH>;
		qos = <15>;

		sysmmu,secure-irq;
		sysmmu,secure_base = <0x18090000>;
		sysmmu,tlb_property =
			<(SYSMMU_PORT_PREFETCH_PREDICTION_READ(0x0)      | SYSMMU_BL8) SYSMMU_NOID>,
			<(SYSMMU_PORT_PREFETCH_PREDICTION_READ(0x1)      | SYSMMU_BL8) SYSMMU_ID_MASK(0x4, 0x7)>,
			<(SYSMMU_PORT_PREFETCH_PREDICTION_WRITE(0x1)     | SYSMMU_BL8) SYSMMU_ID_MASK(0x0, 0x7)>,
			<(SYSMMU_PORT_PREFETCH_PREDICTION_WRITE(0x1)     | SYSMMU_BL8) SYSMMU_ID_MASK(0x4, 0x7)>,
			<(SYSMMU_PORT_PREFETCH_PREDICTION_READWRITE(0x1) | SYSMMU_BL2) SYSMMU_ID_MASK(0x1, 0x1)>;
		port-name = "CLAHE";
		#iommu-cells = <0>;
		power-domains = <&pd_vra>;
	};

	sysmmu_mfc0: sysmmu@18670000 {
		compatible = "samsung,exynos-sysmmu";
		reg = <0x0 0x18670000 0x9000>;
		interrupts = <0 INTREQ__SYSMMU_MFC0D0_interrupt_s1_ns IRQ_TYPE_LEVEL_HIGH>,
			     <0 INTREQ__SYSMMU_MFC0D0_interrupt_s1_s IRQ_TYPE_LEVEL_HIGH>;
		qos = <15>;

		sysmmu,secure-irq;
		sysmmu,secure_base = <0x18680000>;
		sysmmu,tlb_property =
			<(SYSMMU_PORT_NO_PREFETCH_READ(0x0) | SYSMMU_BL8) SYSMMU_NOID>;
		port-name = "MFC port0";
		#iommu-cells = <0>;
		power-domains = <&pd_mfc0>;
	};

	sysmmu_mfc1: sysmmu@186A0000 {
		compatible = "samsung,exynos-sysmmu";
		reg = <0x0 0x186A0000 0x9000>;
		interrupts = <0 INTREQ__SYSMMU_MFC0D1_interrupt_s1_ns IRQ_TYPE_LEVEL_HIGH>,
			     <0 INTREQ__SYSMMU_MFC0D1_interrupt_s1_s IRQ_TYPE_LEVEL_HIGH>;
		qos = <15>;

		sysmmu,secure-irq;
		sysmmu,secure_base = <0x186B0000>;
		sysmmu,tlb_property =
			<(SYSMMU_PORT_NO_PREFETCH_READ(0x0)      | SYSMMU_BL8) SYSMMU_NOID>,
			<(SYSMMU_PORT_NO_PREFETCH_READWRITE(0x1) | SYSMMU_BL2) SYSMMU_ID_MASK(0x1, 0x1)>;
		port-name = "MFC port1, WFD";
		#iommu-cells = <0>;
		power-domains = <&pd_mfc0>;
	};
};
